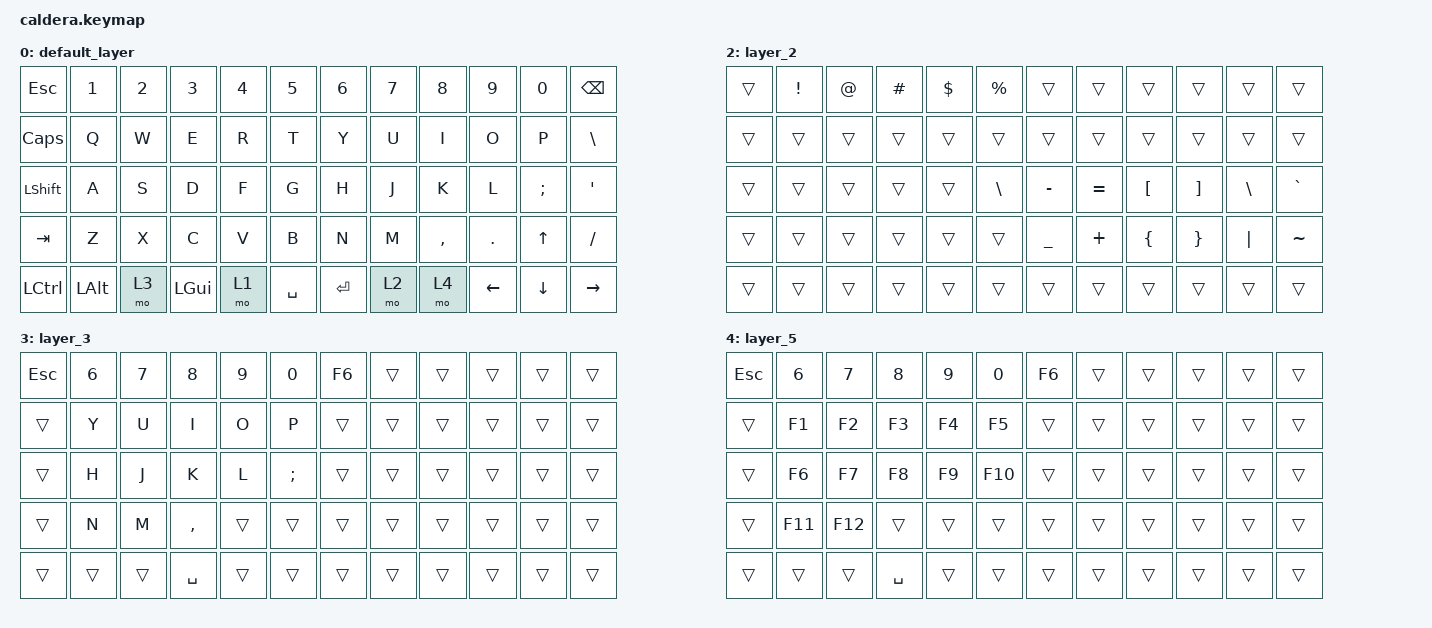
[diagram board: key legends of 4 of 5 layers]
#include <behaviors.dtsi>
#include <dt-bindings/zmk/bt.h>
#include <dt-bindings/zmk/keys.h>

/ {
    macros {
        desktopleft: desktopleft {
            compatible = "zmk,behavior-macro";
            #binding-cells = <0>;
            bindings = <&kp LEFT_WIN &kp LCTRL &kp LEFT>, <&macro_press>;

            label = "DESKTOPLEFT";
        };

        desktopright: desktopright {
            compatible = "zmk,behavior-macro";
            #binding-cells = <0>;
            bindings = <&none &kp LEFT_GUI &kp LEFT_CONTROL &kp RIGHT>;
            label = "DESKTOPRIGHT";
        };
    };

    combos {
        compatible = "zmk,combos";

        fda {
            bindings = <&none>;
            key-positions = <26 39 50>;
        };
    };

    keymap {
        compatible = "zmk,keymap";

        default_layer {
            // ---------------------------------------------------------------------------------
            // |   `  |  1  |  2  |  3  |  4  |  5  |     |  6  |  7  |  8  |  9  |  0  | BKSP |
            // |  TAB |  Q  |  W  |  E  |  R  |  T  |     |  Y  |  U  |  I  |  O  |  P  |  \   |
            // | CAPS |  A  |  S  |  D  |  F  |  G  |     |  H  |  J  |  K  |  L  |  ;  |  ENT |
            // | SHFT |  Z  |  X  |  C  |  V  |  B  |     |  N  |  M  |  ,  |  .  |  /  | APOS |
            // | CTRL | ALT | GUI | SPC | SPC | SPC |     | SPC | LOW |LARW |DARW |UARW | RARW |

            bindings = <
&kp ESCAPE      &kp N1    &kp N2  &kp N3        &kp N4  &kp N5       &kp N6     &kp N7  &kp N8     &kp N9    &kp N0        &kp BSPC
&kp CAPSLOCK    &kp Q     &kp W   &kp E         &kp R   &kp T        &kp Y      &kp U   &kp I      &kp O     &kp P         &kp BSLH
&kp LEFT_SHIFT  &kp A     &kp S   &kp D         &kp F   &kp G        &kp H      &kp J   &kp K      &kp L     &kp SEMI      &kp SQT
&kp TAB         &kp Z     &kp X   &kp C         &kp V   &kp B        &kp N      &kp M   &kp COMMA  &kp DOT   &kp UP_ARROW  &kp SLASH
&kp LCTRL       &kp LALT  &mo 3   &kp LEFT_GUI  &mo 1   &kp SPACE    &kp ENTER  &mo 2   &mo 4      &kp LEFT  &kp DOWN      &kp RIGHT
            >;
        };

        lower_layer {
            // ------------------------------------------------------------------------------------------------------------
            // |       |  BT1  |  BT2  |  BT3  |  BT4  |  BT5  |          |       |       |       |       |       | BTCLR |
            // |       |       |       |       |       |       |          |       |       |       |       |       |       |
            // |       |       |       | LPAR  | RPAR  |       |          |       | LBKT  | RBKT  |       |       |       |
            // |       |       |       |       |       |       |          |       |       |       |       |       |       |

            bindings = <
&kp DELETE   &bt BT_SEL 0      &bt BT_SEL 1       &bt BT_SEL 2  &bt BT_SEL 3   &bt BT_SEL 4    &bt BT_CLR      &trans     &trans            &trans             &trans                &trans
&kp LS(F10)  &kp NUMBER_1      &kp NUMBER_2       &kp NUMBER_3  &kp NUMBER_4   &kp N5          &kp N6          &kp N7     &kp N8            &kp N9             &kp N0                &kp BSPC
&trans       &kp LC(LG(LEFT))  &kp LG(LC(RIGHT))  &kp LA(F4)    &kp LEFT_ALT   &kp TAB         &kp MINUS       &kp EQUAL  &kp LEFT_BRACKET  &kp RIGHT_BRACKET  &kp NON_US_BACKSLASH  &kp GRAVE
&trans       &kp C_VOL_DN      &kp C_VOLUME_UP    &kp C_MUTE    &kp BACKSPACE  &kp KP_ENTER    &kp UNDERSCORE  &kp PLUS   &kp LEFT_BRACE    &kp RIGHT_BRACE    &kp PIPE              &kp TILDE
            >;
        };

        layer_2 {
            bindings = <
&trans  &kp EXCLAMATION  &kp AT_SIGN  &kp HASH  &kp DOLLAR  &kp PERCENT    &trans          &trans     &trans          &trans           &trans    &trans
&trans  &trans           &trans       &trans    &trans      &trans         &trans          &trans     &trans          &trans           &trans    &trans
&trans  &trans           &trans       &trans    &trans      &kp BSLH       &kp MINUS       &kp EQUAL  &kp LBKT        &kp RBKT         &kp BSLH  &kp GRAVE
&trans  &trans           &trans       &trans    &trans      &trans         &kp UNDERSCORE  &kp PLUS   &kp LEFT_BRACE  &kp RIGHT_BRACE  &kp PIPE  &kp TILDE
&trans  &trans           &trans       &trans    &trans      &trans         &trans          &trans     &trans          &trans           &trans    &trans
            >;
        };

        layer_3 {
            bindings = <
&kp ESCAPE  &kp N6  &kp N7  &kp N8     &kp N9  &kp N0      &kp F6  &trans  &trans  &trans  &trans  &trans
&trans      &kp Y   &kp U   &kp I      &kp O   &kp P       &trans  &trans  &trans  &trans  &trans  &trans
&trans      &kp H   &kp J   &kp K      &kp L   &kp SEMI    &trans  &trans  &trans  &trans  &trans  &trans
&trans      &kp N   &kp M   &kp COMMA  &trans  &trans      &trans  &trans  &trans  &trans  &trans  &trans
&trans      &trans  &trans  &kp SPACE  &trans  &trans      &trans  &trans  &trans  &trans  &trans  &trans
            >;
        };

        layer_5 {
            bindings = <
&kp ESCAPE  &kp N6   &kp N7   &kp N8     &kp N9  &kp N0     &kp F6  &trans  &trans  &trans  &trans  &trans
&trans      &kp F1   &kp F2   &kp F3     &kp F4  &kp F5     &trans  &trans  &trans  &trans  &trans  &trans
&trans      &kp F6   &kp F7   &kp F8     &kp F9  &kp F10    &trans  &trans  &trans  &trans  &trans  &trans
&trans      &kp F11  &kp F12  &trans     &trans  &trans     &trans  &trans  &trans  &trans  &trans  &trans
&trans      &trans   &trans   &kp SPACE  &trans  &trans     &trans  &trans  &trans  &trans  &trans  &trans
            >;
        };
    };
};
